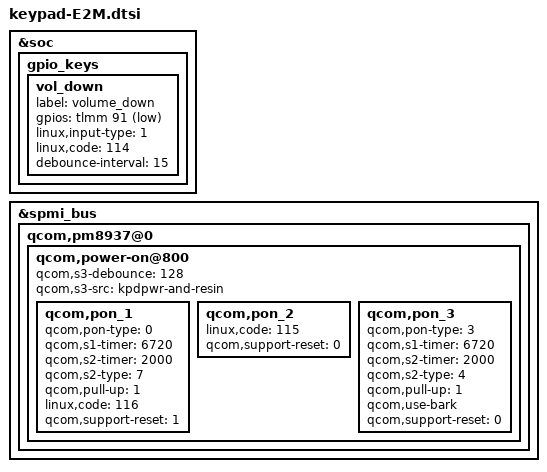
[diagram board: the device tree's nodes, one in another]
&soc {
	gpio_keys {
		/delete-node/ vol_up;
		/delete-node/ camera_focus;
		/delete-node/ camera_snapshot;

		vol_down {
			label = "volume_down";
			gpios = <&tlmm 91 0x1>;
			linux,input-type = <1>;
			linux,code = <114>;
			debounce-interval = <15>;
		};
	};
};

&spmi_bus {
	qcom,pm8937@0 {
		qcom,power-on@800 {
			qcom,s3-debounce = <128>;
			qcom,s3-src = "kpdpwr-and-resin";

			/* PON: KPDPWR */
			qcom,pon_1 {
				qcom,pon-type = <0>;
				qcom,s1-timer = <6720>;
				qcom,s2-timer = <2000>;
				qcom,s2-type = <7>;  /* 1=WARN_RESET, 4=SHUTDOWN, 7=HARD_RESET */
				qcom,pull-up = <1>;
				linux,code = <116>;
				qcom,support-reset = <1>;
			};

			/* PON: RESIN */
			qcom,pon_2 {
				linux,code = <115>;
				qcom,support-reset = <0>;
			};

			/* PON: KPDPWR + RESIN */
			qcom,pon_3 {
				qcom,pon-type = <3>;
				qcom,s1-timer = <6720>;
				qcom,s2-timer = <2000>;
				qcom,s2-type = <4>;  /* 1=WARN_RESET, 4=SHUTDOWN, 7=HARD_RESET */
				qcom,pull-up = <1>;
				qcom,use-bark;
				qcom,support-reset = <0>;
			};
		};
	};
};
